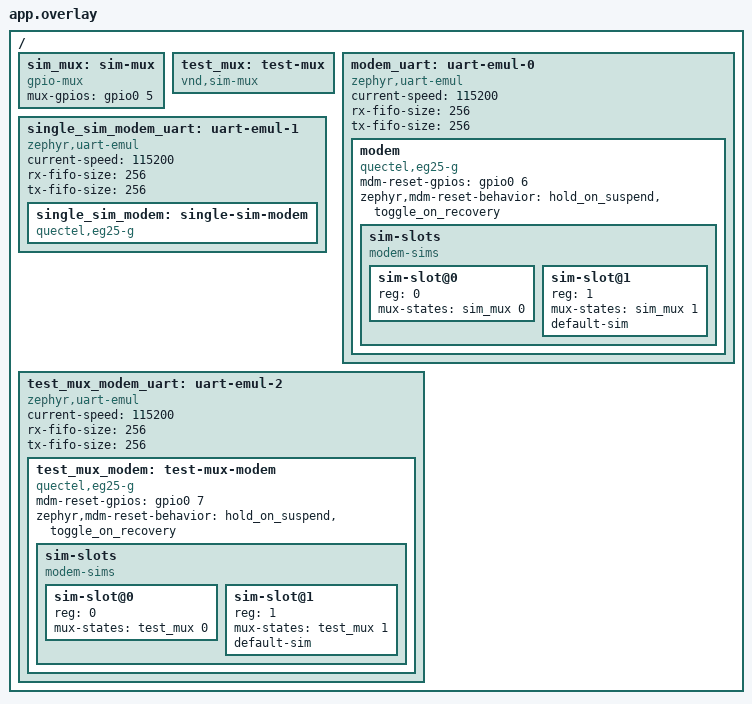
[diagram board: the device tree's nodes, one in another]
/*
 * Copyright (c) 2026 Pedro Ramos
 *
 * SPDX-License-Identifier: Apache-2.0
 *
 * Three modem_cellular instances on emulated UARTs. The first has two SIM slots,
 * switched by one emulated GPIO through a gpio-mux, the second a single SIM, and
 * the third two SIM slots on a test MUX that can be made to fail. The modems with
 * SIM slots are held in reset while suspended, which powers them off.
 */

#include <zephyr/dt-bindings/gpio/gpio.h>

/ {
	sim_mux: sim-mux {
		compatible = "gpio-mux";
		#mux-control-cells = <0>;
		#mux-state-cells = <1>;
		mux-gpios = <&gpio0 5 GPIO_ACTIVE_HIGH>;
	};

	test_mux: test-mux {
		compatible = "vnd,sim-mux";
		#mux-control-cells = <0>;
		#mux-state-cells = <1>;
	};

	modem_uart: uart-emul-0 {
		compatible = "zephyr,uart-emul";
		current-speed = <115200>;
		rx-fifo-size = <256>;
		tx-fifo-size = <256>;
		status = "okay";

		modem: modem {
			compatible = "quectel,eg25-g";
			mdm-reset-gpios = <&gpio0 6 GPIO_ACTIVE_HIGH>;
			zephyr,mdm-reset-behavior = "hold_on_suspend", "toggle_on_recovery";
			status = "okay";

			sim-slots {
				compatible = "modem-sims";
				#address-cells = <1>;
				#size-cells = <0>;

				sim-slot@0 {
					reg = <0>;
					mux-states = <&sim_mux 0>;
				};

				sim-slot@1 {
					reg = <1>;
					mux-states = <&sim_mux 1>;
					default-sim;
				};
			};
		};
	};

	single_sim_modem_uart: uart-emul-1 {
		compatible = "zephyr,uart-emul";
		current-speed = <115200>;
		rx-fifo-size = <256>;
		tx-fifo-size = <256>;
		status = "okay";

		single_sim_modem: single-sim-modem {
			compatible = "quectel,eg25-g";
			status = "okay";
		};
	};

	test_mux_modem_uart: uart-emul-2 {
		compatible = "zephyr,uart-emul";
		current-speed = <115200>;
		rx-fifo-size = <256>;
		tx-fifo-size = <256>;
		status = "okay";

		test_mux_modem: test-mux-modem {
			compatible = "quectel,eg25-g";
			mdm-reset-gpios = <&gpio0 7 GPIO_ACTIVE_HIGH>;
			zephyr,mdm-reset-behavior = "hold_on_suspend", "toggle_on_recovery";
			status = "okay";

			sim-slots {
				compatible = "modem-sims";
				#address-cells = <1>;
				#size-cells = <0>;

				sim-slot@0 {
					reg = <0>;
					mux-states = <&test_mux 0>;
				};

				sim-slot@1 {
					reg = <1>;
					mux-states = <&test_mux 1>;
					default-sim;
				};
			};
		};
	};
};
